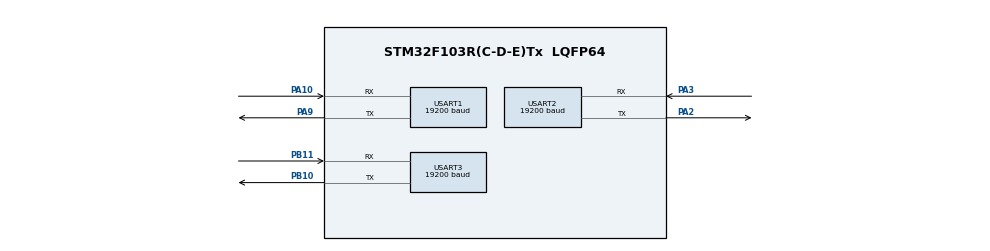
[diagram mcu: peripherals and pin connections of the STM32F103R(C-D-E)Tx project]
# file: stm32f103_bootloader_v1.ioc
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Dma.Request0=USART1_RX
Dma.Request1=USART1_TX
Dma.Request2=USART2_RX
Dma.Request3=USART2_TX
Dma.Request4=USART3_RX
Dma.Request5=USART3_TX
Dma.USART1_RX.0.Direction=DMA_PERIPH_TO_MEMORY
Dma.USART1_RX.0.Instance=DMA1_Channel5
Dma.USART1_RX.0.MemDataAlignment=DMA_MDATAALIGN_BYTE
Dma.USART1_RX.0.MemInc=DMA_MINC_ENABLE
Dma.USART1_RX.0.Mode=DMA_NORMAL
Dma.USART1_RX.0.PeriphDataAlignment=DMA_PDATAALIGN_BYTE
Dma.USART1_RX.0.PeriphInc=DMA_PINC_DISABLE
Dma.USART1_RX.0.Priority=DMA_PRIORITY_LOW
Dma.USART1_TX.1.Direction=DMA_MEMORY_TO_PERIPH
Dma.USART1_TX.1.Instance=DMA1_Channel4
Dma.USART1_TX.1.MemDataAlignment=DMA_MDATAALIGN_BYTE
Dma.USART1_TX.1.MemInc=DMA_MINC_ENABLE
Dma.USART1_TX.1.Mode=DMA_NORMAL
Dma.USART1_TX.1.PeriphDataAlignment=DMA_PDATAALIGN_BYTE
Dma.USART1_TX.1.PeriphInc=DMA_PINC_DISABLE
Dma.USART1_TX.1.Priority=DMA_PRIORITY_LOW
Dma.USART2_RX.2.Direction=DMA_PERIPH_TO_MEMORY
Dma.USART2_RX.2.Instance=DMA1_Channel6
Dma.USART2_RX.2.MemDataAlignment=DMA_MDATAALIGN_BYTE
Dma.USART2_RX.2.MemInc=DMA_MINC_ENABLE
Dma.USART2_RX.2.Mode=DMA_NORMAL
Dma.USART2_RX.2.PeriphDataAlignment=DMA_PDATAALIGN_BYTE
Dma.USART2_RX.2.PeriphInc=DMA_PINC_DISABLE
Dma.USART2_RX.2.Priority=DMA_PRIORITY_LOW
Dma.USART2_TX.3.Direction=DMA_MEMORY_TO_PERIPH
Dma.USART2_TX.3.Instance=DMA1_Channel7
Dma.USART2_TX.3.MemDataAlignment=DMA_MDATAALIGN_BYTE
Dma.USART2_TX.3.MemInc=DMA_MINC_ENABLE
Dma.USART2_TX.3.Mode=DMA_NORMAL
Dma.USART2_TX.3.PeriphDataAlignment=DMA_PDATAALIGN_BYTE
Dma.USART2_TX.3.PeriphInc=DMA_PINC_DISABLE
Dma.USART2_TX.3.Priority=DMA_PRIORITY_LOW
Dma.USART3_RX.4.Direction=DMA_PERIPH_TO_MEMORY
Dma.USART3_RX.4.Instance=DMA1_Channel3
Dma.USART3_RX.4.MemDataAlignment=DMA_MDATAALIGN_BYTE
Dma.USART3_RX.4.MemInc=DMA_MINC_ENABLE
Dma.USART3_RX.4.Mode=DMA_NORMAL
Dma.USART3_RX.4.PeriphDataAlignment=DMA_PDATAALIGN_BYTE
Dma.USART3_RX.4.PeriphInc=DMA_PINC_DISABLE
Dma.USART3_RX.4.Priority=DMA_PRIORITY_LOW
Dma.USART3_TX.5.Direction=DMA_MEMORY_TO_PERIPH
Dma.USART3_TX.5.Instance=DMA1_Channel2
Dma.USART3_TX.5.MemDataAlignment=DMA_MDATAALIGN_BYTE
Dma.USART3_TX.5.MemInc=DMA_MINC_ENABLE
Dma.USART3_TX.5.Mode=DMA_NORMAL
Dma.USART3_TX.5.PeriphDataAlignment=DMA_PDATAALIGN_BYTE
Dma.USART3_TX.5.PeriphInc=DMA_PINC_DISABLE
Dma.USART3_TX.5.Priority=DMA_PRIORITY_LOW
Mcu.Family=STM32F1
Mcu.Name=STM32F103R(C-D-E)Tx
Mcu.Package=LQFP64
NVIC.DMA1_Channel2_IRQn=true\:0\:0\:false\:false\:true\:false\:true\:true
NVIC.DMA1_Channel3_IRQn=true\:0\:0\:false\:false\:true\:false\:true\:true
NVIC.DMA1_Channel4_IRQn=true\:0\:0\:false\:false\:true\:false\:true\:true
NVIC.DMA1_Channel5_IRQn=true\:0\:0\:false\:false\:true\:false\:true\:true
NVIC.DMA1_Channel6_IRQn=true\:0\:0\:false\:false\:true\:false\:true\:true
NVIC.DMA1_Channel7_IRQn=true\:0\:0\:false\:false\:true\:false\:true\:true
NVIC.PriorityGroup=NVIC_PRIORITYGROUP_4
NVIC.USART1_IRQn=true\:0\:0\:false\:false\:true\:false\:true\:true
NVIC.USART2_IRQn=true\:0\:0\:false\:false\:true\:false\:true\:true
NVIC.USART3_IRQn=true\:0\:0\:false\:false\:true\:false\:true\:true
PA10.Mode=Asynchronous
PA10.Signal=USART1_RX
PA13.Mode=Serial_Wire
PA13.Signal=SYS_JTMS-SWDIO
PA14.Mode=Serial_Wire
PA14.Signal=SYS_JTCK-SWCLK
PA2.Mode=Asynchronous
PA2.Signal=USART2_TX
PA3.Mode=Asynchronous
PA3.Signal=USART2_RX
PA9.Mode=Asynchronous
PA9.Signal=USART1_TX
PB10.Mode=Asynchronous
PB10.Signal=USART3_TX
PB11.Mode=Asynchronous
PB11.Signal=USART3_RX
ProjectManager.HeapSize=0x200
ProjectManager.StackSize=0x400
ProjectManager.TargetToolchain=MDK-ARM V5.32
RCC.AHBFreq_Value=64000000
RCC.APB1CLKDivider=RCC_HCLK_DIV2
RCC.APB1Freq_Value=32000000
RCC.APB1TimFreq_Value=64000000
RCC.APB2Freq_Value=64000000
RCC.APB2TimFreq_Value=64000000
RCC.HCLKFreq_Value=64000000
RCC.PLLMUL=RCC_PLL_MUL16
RCC.SYSCLKFreq_VALUE=64000000
RCC.SYSCLKSource=RCC_SYSCLKSOURCE_PLLCLK
RCC.USBFreq_Value=64000000
USART1.BaudRate=19200
USART1.VirtualMode=VM_ASYNC
USART2.BaudRate=19200
USART2.VirtualMode=VM_ASYNC
USART3.BaudRate=19200
USART3.VirtualMode=VM_ASYNC
board=custom

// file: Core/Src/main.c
/* USER CODE BEGIN Header */
/**
  ******************************************************************************
  * @file           : main.c
  * @brief          : Main program body
  ******************************************************************************
  * @attention
  *
  * Copyright (c) 2026 STMicroelectronics.
  * All rights reserved.
  *
  * This software is licensed under terms that can be found in the LICENSE file
  * in the root directory of this software component.
  * If no LICENSE file comes with this software, it is provided AS-IS.
  *
  ******************************************************************************
  */
/* USER CODE END Header */
#include "main.h"
#include "dma.h"
#include "usart.h"
#include "gpio.h"

/* USER CODE BEGIN Includes */
#include "bootloader.h"
/* USER CODE END Includes */

void SystemClock_Config(void);

int main(void)
{

  /* MCU Configuration--------------------------------------------------------*/

  /* Reset of all peripherals, Initializes the Flash interface and the Systick. */
  HAL_Init();

  /* Configure the system clock */
  SystemClock_Config();

  /* USER CODE BEGIN SysInit */
#if BL_ENABLE_CH9121
  ch9121_gpio_init();
#endif
  /* USER CODE END SysInit */

  /* Initialize all configured peripherals */
  MX_GPIO_Init();
  MX_DMA_Init();
#if BL_ENABLE_USART1
  MX_USART1_UART_Init();
#endif
#if BL_ENABLE_USART2
  MX_USART2_UART_Init();
#endif
#if BL_ENABLE_USART3
  MX_USART3_UART_Init();
#endif
  /* USER CODE BEGIN 2 */
	boot_uart_config();
	poweron_self_check();
  /* USER CODE END 2 */

  /* Infinite loop */
  while (1)
  {
	  bsp_ota_handle();
  }
}

void SystemClock_Config(void)
{
  LL_FLASH_SetLatency(LL_FLASH_LATENCY_2);
  while(LL_FLASH_GetLatency()!= LL_FLASH_LATENCY_2)
  {
  }
  LL_RCC_HSI_SetCalibTrimming(16);
  LL_RCC_HSI_Enable();

   /* Wait till HSI is ready */
  while(LL_RCC_HSI_IsReady() != 1)
  {

  }
  LL_RCC_PLL_ConfigDomain_SYS(LL_RCC_PLLSOURCE_HSI_DIV_2, LL_RCC_PLL_MUL_16);
  LL_RCC_PLL_Enable();

   /* Wait till PLL is ready */
  while(LL_RCC_PLL_IsReady() != 1)
  {

  }
  LL_RCC_SetAHBPrescaler(LL_RCC_SYSCLK_DIV_1);
  LL_RCC_SetAPB1Prescaler(LL_RCC_APB1_DIV_2);
  LL_RCC_SetAPB2Prescaler(LL_RCC_APB2_DIV_1);
  LL_RCC_SetSysClkSource(LL_RCC_SYS_CLKSOURCE_PLL);

   /* Wait till System clock is ready */
  while(LL_RCC_GetSysClkSource() != LL_RCC_SYS_CLKSOURCE_STATUS_PLL)
  {

  }
  LL_SetSystemCoreClock(64000000);

   /* Update the time base */
  if (HAL_InitTick (TICK_INT_PRIORITY) != HAL_OK)
  {
    Error_Handler();
  }
}

void Error_Handler(void)
{
  __disable_irq();
  while (1)
  {
  }
}
